# CH32X315 register map
Vendor: WCH Ltd.; File version: 1.1
Registers are 32-bit, read-write, reset 0x0 unless marked. A register's access mark holds for its fields unless they carry their own. Offsets are from the block's base; [hi:lo] are bit positions; {n}, {i} and the like mark numbered series.

## I2C1 — Inter integrated circuit
Base 0x40005400
Same registers: I2C2 0x40005800
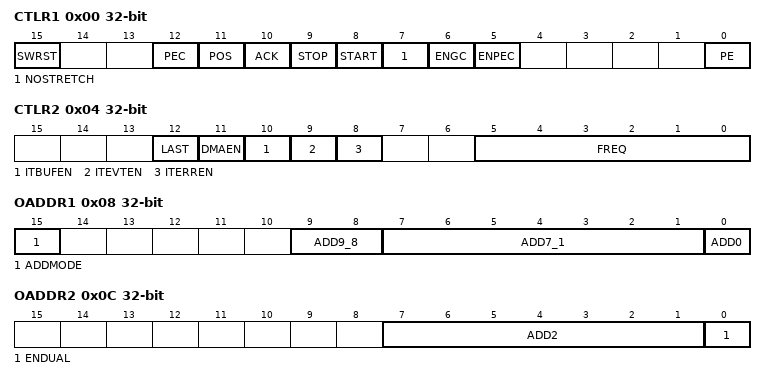
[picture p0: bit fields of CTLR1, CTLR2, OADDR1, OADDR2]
0x00 CTLR1 — Control register 1
  [15] SWRST — Software reset
  [12] PEC — Packet error checking
  [11] POS — Acknowledge/PEC Position (for data reception)
  [10] ACK — Acknowledge enable
  [9] STOP — Stop generation
  [8] START — Start generation
  [7] NOSTRETCH — Clock stretching disable (Slave mode)
  [6] ENGC — General call enable
  [5] ENPEC — PEC enable
  [0] PE — Peripheral enable
0x04 CTLR2 — Control register 2
  [12] LAST — DMA last transfer
  [11] DMAEN — DMA requests enable
  [10] ITBUFEN — Buffer interrupt enable
  [9] ITEVTEN — Event interrupt enable
  [8] ITERREN — Error interrupt enable
  [5:0] FREQ — Peripheral clock frequency
0x08 OADDR1 — Own address register 1
  [15] ADDMODE — Addressing mode (slave mode)
  [9:8] ADD9_8 — Interface address
  [7:1] ADD7_1 — Interface address
  [0] ADD0 — Interface address
0x0C OADDR2 — Own address register 2
  [7:1] ADD2 — Interface address
  [0] ENDUAL — Dual addressing mode enable
0x10 DATAR — Data register
  [7:0] DATAR — 8-bit data register
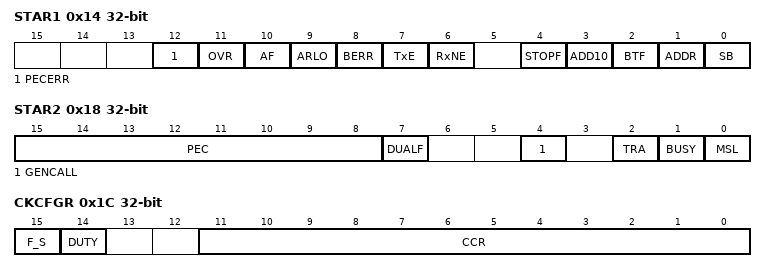
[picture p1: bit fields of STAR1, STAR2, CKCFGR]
0x14 STAR1 access per field — Status register 1
  [12] PECERR rw — PEC Error in reception
  [11] OVR rw — Overrun/Underrun
  [10] AF rw — Acknowledge failure
  [9] ARLO rw — Arbitration lost (master mode)
  [8] BERR rw — Bus error
  [7] TxE ro — Data register empty (transmitters)
  [6] RxNE ro — Data register not empty (receivers)
  [4] STOPF ro — Stop detection (slave mode)
  [3] ADD10 ro — 10-bit header sent (Master mode)
  [2] BTF ro — Byte transfer finished
  [1] ADDR ro — Address sent (master mode)/matched (slave mode)
  [0] SB ro — Start bit (Master mode)
0x18 STAR2 ro — Status register 2
  [15:8] PEC — acket error checking register
  [7] DUALF — Dual flag (Slave mode)
  [4] GENCALL — General call address (Slave mode)
  [2] TRA — Transmitter/receiver
  [1] BUSY — Bus busy
  [0] MSL — Master/slave
0x1C CKCFGR — Clock control register
  [15] F_S — I2C master mode selection
  [14] DUTY — Fast mode duty cycle
  [11:0] CCR — Clock control register in Fast/Standard mode (Master mode)

## SPI1 — Serial peripheral interface
Base 0x40013000
Same registers: SPI2 0x40003800, SPI3 0x40003C00
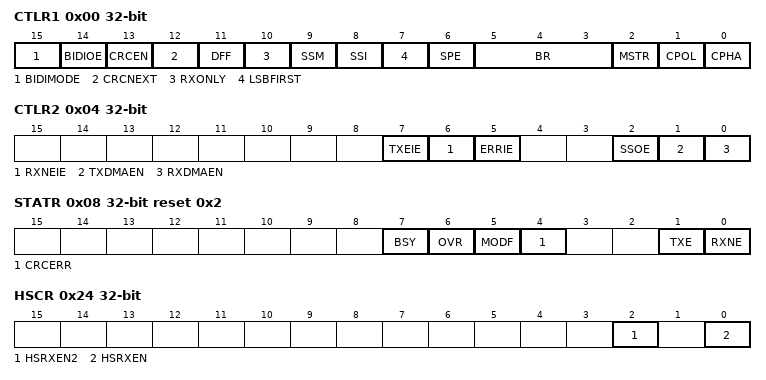
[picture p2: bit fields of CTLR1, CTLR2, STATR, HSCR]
0x00 CTLR1 — control register 1
  [15] BIDIMODE — Bidirectional data mode enable
  [14] BIDIOE — Output enable in bidirectional mode
  [13] CRCEN — Hardware CRC calculation enable
  [12] CRCNEXT — CRC transfer next
  [11] DFF — Data frame format
  [10] RXONLY — Receive only
  [9] SSM — Software slave management
  [8] SSI — Internal slave select
  [7] LSBFIRST — Frame format
  [6] SPE — SPI enable
  [5:3] BR — Baud rate control
  [2] MSTR — Master selection
  [1] CPOL — Clock polarity
  [0] CPHA — Clock phase
0x04 CTLR2 — control register 2
  [7] TXEIE — Tx buffer empty interrupt enable
  [6] RXNEIE — RX buffer not empty interrupt enable
  [5] ERRIE — Error interrupt enable
  [2] SSOE — SS output enable
  [1] TXDMAEN — Tx buffer DMA enable
  [0] RXDMAEN — Rx buffer DMA enable
0x08 STATR access per field reset 0x2 — status register
  [7] BSY ro — Busy flag
  [6] OVR ro — Overrun flag
  [5] MODF ro — Mode fault
  [4] CRCERR rw — CRC error flag
  [1] TXE ro — Transmit buffer empty
  [0] RXNE ro — Receive buffer not empty
0x0C DATAR — data register
  [15:0] DR — Data register
0x10 CRCR reset 0x7 — CRCR polynomial register
  [15:0] CRCPOLY — CRC polynomial register
0x14 RCRCR ro — RX CRC register
  [15:0] RXCRC
0x18 TCRCR ro — TX CRC register
  [15:0] TXCRC
0x24 HSCR — high speed control register
  [2] HSRXEN2 — High speed mode 2 read enable
  [0] HSRXEN — High speed mode read enable

## USBPD — USBPD configuration
Base 0x40024400
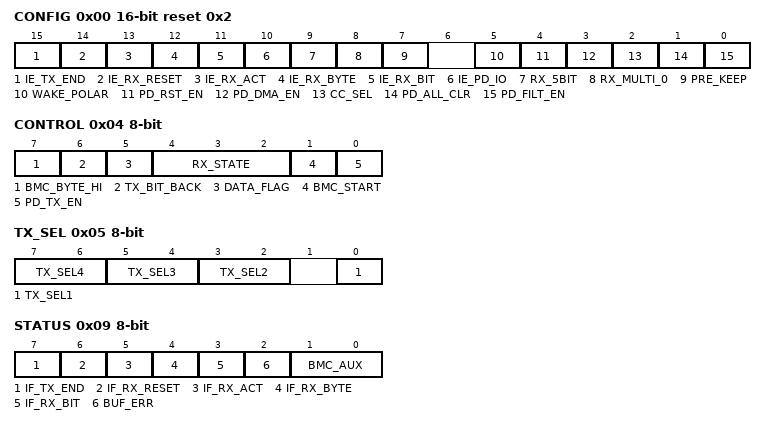
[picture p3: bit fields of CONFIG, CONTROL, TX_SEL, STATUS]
0x00 CONFIG 16-bit access per field reset 0x2 — PD interrupt enable register
  [15] IE_TX_END rw — transfer complete interrupt register
  [14] IE_RX_RESET rw — Receive complete rst interrupt register
  [13] IE_RX_ACT rw — Receive complete interrupt register
  [12] IE_RX_BYTE rw — Receive byte interrupt register
  [11] IE_RX_BIT rw — bit interrupt Enable
  [10] IE_PD_IO rw — PD IO interrupt Enable
  [9] RX_5BIT ro — PD receive a status indication of 5 valid data bits
  [8] RX_MULTI_0 ro — Continuously receive several bits of 0 indicator flag
  [7] PRE_KEEP rw — Preamble transmission status maintaining controller
  [5] WAKE_POLAR rw — wakeup polarity
  [4] PD_RST_EN rw — PD RST Enable
  [3] PD_DMA_EN rw — PD DMA Enable
  [2] CC_SEL rw — PD Commutation port
  [1] PD_ALL_CLR rw — PD ITClear
  [0] PD_FILT_EN rw — control PD pin input filter enable
0x02 BMC_CLK_CNT 16-bit — BMC sampling clock counter
  [9:0] BMC_CLK_CNT — R/T counter
0x04 CONTROL 8-bit access per field — PD Send and receive enable register
  [7] BMC_BYTE_HI ro — BMC_BYTE_HI value
  [6] TX_BIT_BACK ro — TX_BIT_BACK value
  [5] DATA_FLAG ro — DATA_FLAG value
  [4:2] RX_STATE rw — PD receive status identification
  [1] BMC_START rw — BMC_START value
  [0] PD_TX_EN rw — PD_TX_EN value
0x05 TX_SEL 8-bit — SOP port selection register
  [7:6] TX_SEL4 — TX_SEL4 value
  [5:4] TX_SEL3 — TX_SEL3 value
  [3:2] TX_SEL2 — TX_SEL2 value
  [0] TX_SEL1 — TX_SEL1 value
0x06 BMC_TX_SZ 16-bit — PD send length register
  [8:0] BMC_TX_SZ — BMC_TX_SZ value
0x08 DATA_BUF 8-bit ro — DMA cache data register
  [7:0] DATA_BUF — DATA_BUF value
0x09 STATUS 8-bit access per field — PD interrupt flag register
  [7] IF_TX_END rw — IF_TX_END value
  [6] IF_RX_RESET rw — IF_RX_RESET value
  [5] IF_RX_ACT rw — IF_RX_ACT value
  [4] IF_RX_BYTE rw — IF_RX_BYTE value
  [3] IF_RX_BIT rw — IF_RX_BIT value
  [2] BUF_ERR rw — BUF_ERR value
  [1:0] BMC_AUX ro — BMC_AUX value
0x0A BMC_BYTE_CNT 16-bit ro — Byte counter
  [8:0] BMC_BYTE_CNT — BMC_BYTE_CNT value
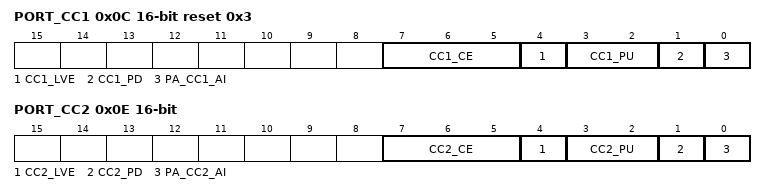
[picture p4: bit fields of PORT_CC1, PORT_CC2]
0x0C PORT_CC1 16-bit access per field reset 0x3 — CC1 port control register
  [7:5] CC1_CE rw — CC1_CE value
  [4] CC1_LVE rw — CC1_LVE value
  [3:2] CC1_PU rw — CC1_PU value
  [1] CC1_PD rw — port pull-down resistor enable
  [0] PA_CC1_AI ro — PA_CC1_AI value
0x0E PORT_CC2 16-bit — CC2 port control register
  [7:5] CC2_CE — CC2_CE value
  [4] CC2_LVE — CC2_LVE value
  [3:2] CC2_PU — CC2_PU value
  [1] CC2_PD — port pull-down resistor enable
  [0] PA_CC2_AI — PA_CC2_AI value
0x10 DMA — PD buffer start address register
  [15:0] USBPD_DMA_ADDR — USBPD_DMA_ADDR value

## ESIG — ESIG configuration
Base 0x1FFFF7E0
0x00 FLACAP 16-bit ro — Flash capecity register
  [15:0] F_SIZE — F_SIZE/kByte
0x08 UNIID1 ro — UID register
  [31:0] U_ID — U_ID value
0x0C UNIID2 ro — UID register
  [31:0] U_ID — U_ID value
0x10 UNIID3 ro — Div register
  [31:0] U_ID — U_ID value

## FLASH
Base 0x40022000
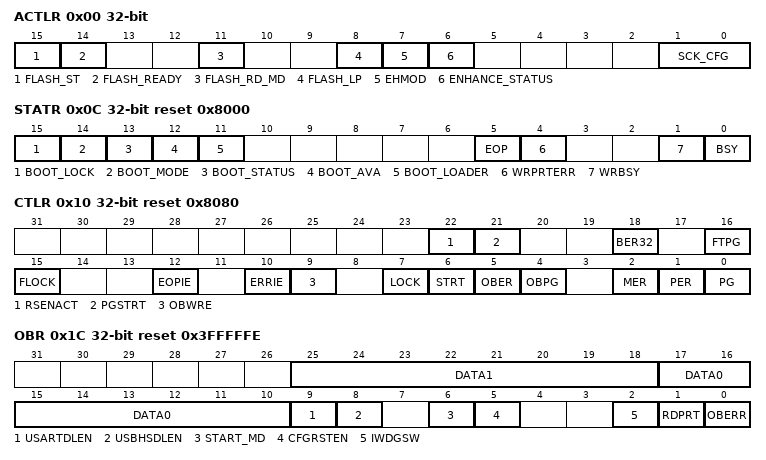
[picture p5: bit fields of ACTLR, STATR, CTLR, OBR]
0x00 ACTLR access per field — Access control register
  [15] FLASH_ST ro — FLASH Low Power Status Indicator Bits
  [14] FLASH_READY ro — flash ready indicator
  [11] FLASH_RD_MD rw — FLASH read mode control bit
  [8] FLASH_LP rw — FLASH Low Power Mode Control Bit
  [7] EHMOD rw — flash enhanced read mode control bit
  [6] ENHANCE_STATUS ro — Enhanced Status
  [1:0] SCK_CFG rw — FLASH clock SCK frequency configuration bit
0x04 KEYR wo — Flash key register
  [31:0] KEYR — FPEC key
0x08 OBKEYR wo — Flash option key register
  [31:0] OBTKEY — Option byte key
0x0C STATR access per field reset 0x8000 — Status register
  [15] BOOT_LOCK rw
  [14] BOOT_MODE rw
  [13] BOOT_STATUS ro
  [12] BOOT_AVA ro
  [11] BOOT_LOADER ro — the current position indicator of the program running
  [5] EOP rw — End of operation
  [4] WRPRTERR rw — Write protection error
  [1] WRBSY ro — Quick page programming
  [0] BSY ro — Busy
0x10 CTLR reset 0x8080 — Control register
  [22] RSENACT — Reset Flash Enhance read mode
  [21] PGSTRT — Page Programming Start
  [18] BER32 — Block Erase
  [16] FTPG — Fast programming
  [15] FLOCK — Fast programmable lock
  [12] EOPIE — End of operation interrupt enable
  [10] ERRIE — Error interrupt enable
  [9] OBWRE — Option bytes write enable
  [7] LOCK
  [6] STRT — Start
  [5] OBER — Option byte erase
  [4] OBPG — Option byte programming
  [2] MER — Mass Erase
  [1] PER — Page Erase
  [0] PG — Programming
0x14 ADDR wo — Flash address register
  [31:0] FAR — Flash Address
0x1C OBR ro reset 0x3FFFFFE — Option byte register
  [25:18] DATA1 — Data byte 1
  [17:10] DATA0 — Data byte 0
  [9] USARTDLEN — BOOT enables the USART's keyless download function
  [8] USBHSDLEN — BOOT enables the USBHS download function
  [6] START_MD — Startup mode configuration
  [5] CFGRSTEN — external pin reset enable
  [2] IWDGSW
  [1] RDPRT — Read protection
  [0] OBERR — Option byte error
0x20 WPR ro — Write protection register
  [31:0] WRP — Write protect
0x24 MODEKEYR wo — Mode select register
  [31:0] MODEKEYR — Mode select
0x28 BOOT_MODEKEYR wo — Unlock BOOT key register
  [31:0] BOOTKEYR
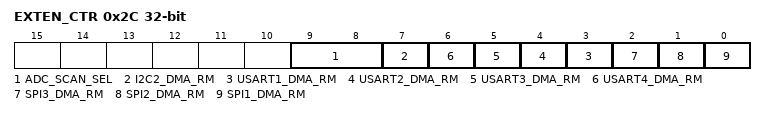
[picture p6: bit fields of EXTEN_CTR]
0x2C EXTEN_CTR — System control register
  [9:8] ADC_SCAN_SEL — Scan cycle counter output ADC selection
  [7] I2C2_DMA_RM — I2C2 DMA channel mapping
  [n+2] USART{n}_DMA_RM (n=1..4) — USART{n} DMA channel mapping
  [2] SPI3_DMA_RM — SPI3 DMA channel mapping
  [1] SPI2_DMA_RM — SPI2 DMA channel mapping
  [0] SPI1_DMA_RM — SPI1 DMA channel mapping
